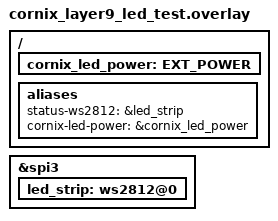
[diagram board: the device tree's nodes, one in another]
&spi3 {
    status = "okay";

    led_strip: ws2812@0 {
        status = "okay";
    };
};

/ {
    cornix_led_power: EXT_POWER {
        status = "okay";
    };

    aliases {
        status-ws2812 = &led_strip;
        cornix-led-power = &cornix_led_power;
    };
};
